# tviic2d6m register map
Vendor: Infineon Technologies; Series: TVIIC2D6M; File version: 1.0
CPU: CM7 r0p1, little endian, MPU, FPU, double-precision FPU, I-cache, D-cache, VTOR, ITCM, DTCM, 3 interrupt priority bits, 16 interrupts
Registers are 32-bit, read-write, reset 0x0 unless marked. A register's access mark holds for its fields unless they carry their own. Offsets are from the block's base; [hi:lo] are bit positions; lines under a group give offsets from that group; {n}, {i} and the like mark numbered series; 'fields as' and 'values as' point back to an identical list; <NAME> marks a mode.

## BACKUP — SRSS Backup Domain (ver3p3)
Base 0x40270000
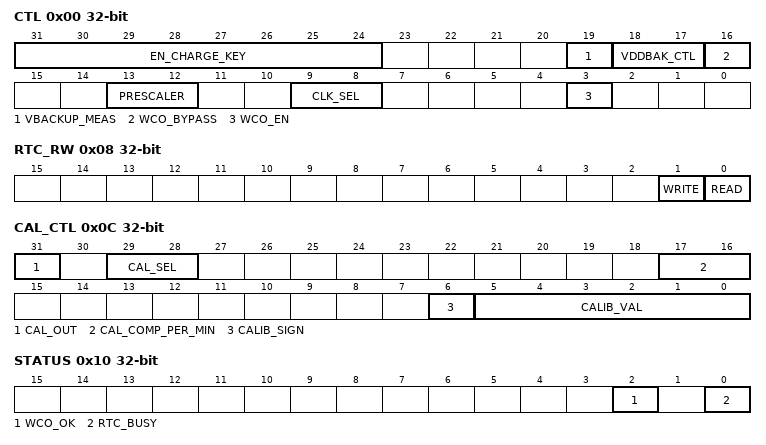
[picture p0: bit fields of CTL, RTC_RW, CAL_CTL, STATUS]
0x00 CTL — Control
  [31:24] EN_CHARGE_KEY — When set to 3C, the supercap charger circuit is enabled. Any other code disables the supercap charger. THIS CHARGING CIRCUIT IS FOR A SUPERCAP ONLY AND CANNOT SAFELY CHARGE A BATTERY. DO NOT WRITE THIS KEY WHEN VBACKUP IS CONNECTED TO A BATTERY.
  [19] VBACKUP_MEAS — Connect vbackup supply to the vbackup_meas output for measurement by an ADC attached to amuxbusa_adft_vddd. The vbackup_meas signal is scaled to 10 percent of vbackup, so it is within the supply range of the ADC.
  [18:17] VDDBAK_CTL — Controls the behavior of the switch that generates vddbak from vbackup or vddd. 0: automatically select vddd if its brownout detector says it is valid. If the brownout says its not valid, then use vmax which is the highest of vddd or vbackup. 1,2,3: force vddbak and vmax to select vbackup, regardless of its voltage.
  [16] WCO_BYPASS — Configures the WCO for different board-level connections to the WCO pins. For example, this can be used to connect an external watch crystal oscillator instead of a watch crystal. In all cases, the two related GPIO pins (WCO input and output pins) must be configured as analog connections using GPIO registers, and they must be hooked at the board level as described below. Configure this field before enabling the WCO, and do not change this setting when WCO_EN=1. 0: Watch crystal. Connect a 32.768 kHz watch crystal between WCO input and output pins. 1: Clock signal, either a square wave or sine wave. See PRESCALER field for connection information.
  [13:12] PRESCALER
  [9:8] CLK_SEL — Clock select for RTC clock
    0=WCO (Watch-crystal oscillator input, available in Active, DeepSleep, Hibernate, and XRES.); 1=ALTBAK (This allows to use the LFCLK selection as an alternate backup domain clock. Note that LFCLK is only available in Active and DeepSleep power modes. Note that LFCLK clock glitches can propagate into the backup logic when the clock is stopped. For this reason, if the WCO or ILO is intended as the clock source then choose it directly instead of routing through LFCLK.); 2=ILO (Internal Low frequency Oscillator, available in Active, DeepSleep, Hibernate, and XRES. For Hibernate operation CLK_ILO_CONFIG. ILO_BACKUP must be set. If there are multiple ILO, this is ILO0.); 3=LPECO_PRESCALER (Low-power external crystal oscillator prescaler output, available in Active, DeepSleep, Hibernate, and XRES.)
  [3] WCO_EN — Watch-crystal oscillator (WCO) enable. If there is a write in progress when this bit is cleared, the WCO will be internally kept on until the write completes. After enabling the WCO software must wait until STATUS.WCO_OK=1 before configuring any component that depends on clk_lf/clk_bak, like for example RTC or WDTs. Follow the procedure in BACKUP_RTC_RW to access this bit.
0x08 RTC_RW — RTC Read Write register
  [1] WRITE — Write bit Only when this bit is set can the RTC registers be written to (otherwise writes are ignored). This bit cannot be set if the RTC is still busy with a previous update (see RTC_BUSY bit) or if the Read bit is set or getting set. The user writes to the RTC user registers, when the Write bit is cleared by the user then the user registers content is copied to the actual RTC registers. Only user RTC registers that were written to will get copied, others will not be affected. When the SECONDS field is updated then TICKS will also be reset (WDT is not affected). When the Write bit is cleared by a reset (brown out/DeepSleep) then the RTC update will be ignored/lost. Do not set the Write bit if the RTC if the RTC is still busy with a previous update (see RTC_BUSY). Do not set the Write bit at the same time that the Read bit is cleared.
  [0] READ — Read bit When this bit is set the RTC registers will be copied to user registers and frozen so that a coherent RTC value can safely be read. The RTC will keep on running. Do not set the read bit if the RTC is still busy with a previous update (see RTC_BUSY bit) or if the Write bit is set. Do not set the Read bit at the same time that the Write bit is cleared.
0x0C CAL_CTL — Oscillator calibration for absolute frequency
  [31] CAL_OUT — Output enable for wave signal for calibration and allow CALIB_VAL to be written.
  [29:28] CAL_SEL — Select calibration wave output signal
    0=CAL512 (512Hz wave, not affected by calibration setting (not supported for 50/60Hz input clock: CTL.PRESCALER!=0)); 1=RSVD (N/A); 2=CAL2 (2Hz wave, includes the effect of the calibration setting, (not supported for 50/60Hz input clock: CTL.PRESCALER!=0)); 3=CAL1 (1Hz wave, includes the effect of the calibration setting (supported for all input clocks))
  [17:16] CAL_COMP_PER_MIN — Select how many time calibration is performed per minute per step of 64 , each time a 64 step is added or substracted one unit 2/4/8/16*CALIB_VAL is substracted.
    0=Calibration of 64 each is performed twice per minute for 2*CALIB_VAL per hour; 1=Calibration of 64 each is performed four times per minute for 4*CALIB_VAL per hour; 2=Calibration of 64 each is performed eight times per minute for 8*CALIB_VAL per hour; 3=Ca6libration of 64 each is performed sixteen times per minute for 16*CALIB_VAL per hour
  [6] CALIB_SIGN — Calibration sign: 0= Negative sign: remove pulses (it takes more clock ticks to count one second) 1= Positive sign: add pulses (it takes less clock ticks to count one second)
  [5:0] CALIB_VAL — Calibration value for absolute frequency (at a fixed temperature). Each step causes 128 ticks to be added or removed each hour. Effectively that means that each step is 1.085ppm (= 128/(60*60*32,768)) when CAL_COMP_PER_MIN is set at default value. Positive values 0x01-0x3c (1..60) add pulses, negative values remove pulses, thus giving a range of +/-65.1 ppm (limited by 60 minutes per hour, not the range of this field) when CAL_COMP_PER_MIN is set at default value . Calibration is performed hourly, starting at 59 minutes and 59 seconds, and applied as 64 ticks every 30 seconds until there have been 2*CALIB_VAL adjustments when CAL_COMP_PER_MIN is set at default value .
0x10 STATUS ro
  [2] WCO_OK — Indicates that output has transitioned.
  [0] RTC_BUSY — Pending RTC write
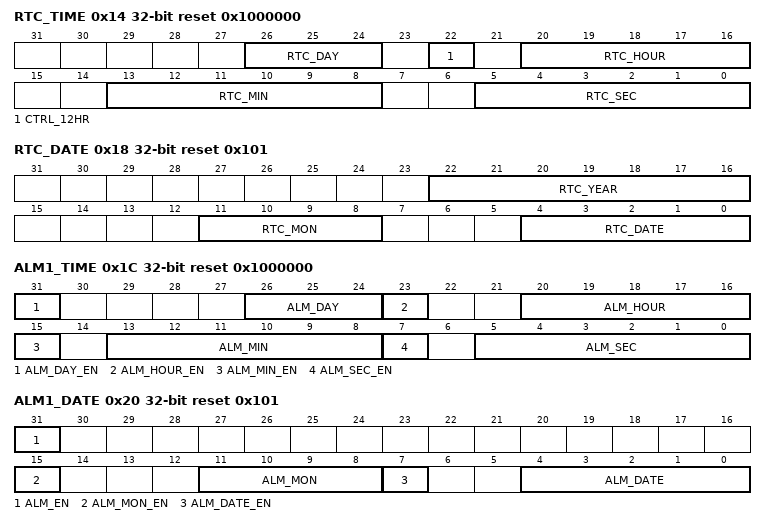
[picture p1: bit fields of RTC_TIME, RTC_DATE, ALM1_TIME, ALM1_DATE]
0x14 RTC_TIME reset 0x1000000 — Calendar Seconds, Minutes, Hours, Day of Week
  [26:24] RTC_DAY — Calendar Day of the week, 1-7 It is up to the user to define the meaning of the values, but 1=Monday is recommended
  [22] CTRL_12HR — Select 12/24HR mode: 1=12HR, 0=24HR
  [20:16] RTC_HOUR — Calendar hours, value depending on 12/24HR mode 0=24HR: [20:16]=0-23 1=12HR: [20]:0=AM, 1=PM, [19:16]=1-12
  [13:8] RTC_MIN — Calendar minutes, 0-59
  [5:0] RTC_SEC — Calendar seconds, 0-59
0x18 RTC_DATE reset 0x101 — Calendar Day of Month, Month, Year
  [22:16] RTC_YEAR — Calendar year, 0-99
  [11:8] RTC_MON — Calendar Month, 1-12
  [4:0] RTC_DATE — Calendar Day of the Month, 1-31 Automatic Leap Year Correction
0x1C ALM1_TIME reset 0x1000000 — Alarm 1 Seconds, Minute, Hours, Day of Week
  [31] ALM_DAY_EN — Alarm Day of the Week enable: 0=ignore, 1=match
  [26:24] ALM_DAY — Alarm Day of the week, 1-7 It is up to the user to define the meaning of the values, but 1=Monday is recommended
  [23] ALM_HOUR_EN — Alarm hour enable: 0=ignore, 1=match
  [20:16] ALM_HOUR — Alarm hours, value depending on 12/24HR mode 24HR: [4:0]=0-23 12HR: [4]:0=AM, 1=PM, [3:0]=1-12
  [15] ALM_MIN_EN — Alarm minutes enable: 0=ignore, 1=match
  [13:8] ALM_MIN — Alarm minutes, 0-59
  [7] ALM_SEC_EN — Alarm second enable: 0=ignore, 1=match
  [5:0] ALM_SEC — Alarm seconds, 0-59
0x20 ALM1_DATE reset 0x101 — Alarm 1 Day of Month, Month
  [31] ALM_EN — Master enable for alarm 1. 0: Alarm 1 is disabled. Fields for date and time are ignored. 1: Alarm 1 is enabled. Alarm triggers whenever the new date and time matches all the enabled date and time fields, which can happen more than once depending on configuration. If none of the date and time fields are enabled, then this alarm triggers once every second.
  [15] ALM_MON_EN — Alarm Month enable: 0=ignore, 1=match
  [11:8] ALM_MON — Alarm Month, 1-12
  [7] ALM_DATE_EN — Alarm Day of the Month enable: 0=ignore, 1=match
  [4:0] ALM_DATE — Alarm Day of the Month, 1-31 Leap Year corrected
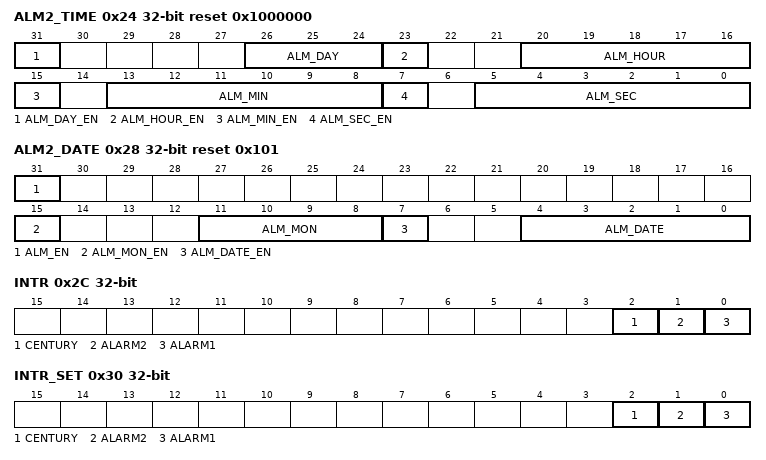
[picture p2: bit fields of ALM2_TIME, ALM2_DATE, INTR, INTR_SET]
0x24 ALM2_TIME reset 0x1000000 — Alarm 2 Seconds, Minute, Hours, Day of Week
  fields as ALM1_TIME
0x28 ALM2_DATE reset 0x101 — Alarm 2 Day of Month, Month
  [31] ALM_EN — Master enable for alarm 2. 0: Alarm 2 is disabled. Fields for date and time are ignored. 1: Alarm 2 is enabled. Alarm triggers whenever the new date and time matches all the enabled date and time fields, which can happen more than once depending on configuration. If none of the date and time fields are enabled, then this alarm triggers once every second.
  [15] ALM_MON_EN — Alarm Month enable: 0=ignore, 1=match
  [11:8] ALM_MON — Alarm Month, 1-12
  [7] ALM_DATE_EN — Alarm Day of the Month enable: 0=ignore, 1=match
  [4:0] ALM_DATE — Alarm Day of the Month, 1-31 Leap Year corrected
0x2C INTR — Interrupt request register
  [2] CENTURY write-1-clears — Century overflow interrupt
  [1] ALARM2 write-1-clears — Alarm 2 Interrupt
  [0] ALARM1 write-1-clears — Alarm 1 Interrupt
0x30 INTR_SET — Interrupt set request register
  [2] CENTURY write-1-sets — Write with '1' to set corresponding bit in interrupt request register.
  [1] ALARM2 write-1-sets — Write with '1' to set corresponding bit in interrupt request register.
  [0] ALARM1 write-1-sets — Write with '1' to set corresponding bit in interrupt request register.
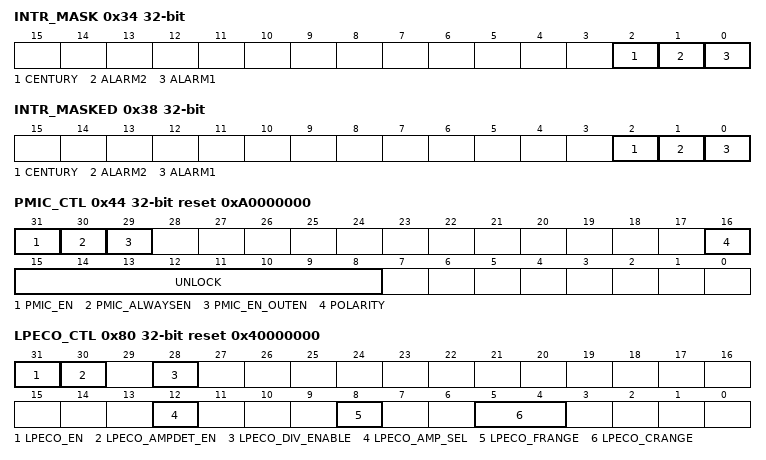
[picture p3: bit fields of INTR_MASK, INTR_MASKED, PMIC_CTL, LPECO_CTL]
0x34 INTR_MASK — Interrupt mask register
  [2] CENTURY — Mask bit for corresponding bit in interrupt request register.
  [1] ALARM2 — Mask bit for corresponding bit in interrupt request register.
  [0] ALARM1 — Mask bit for corresponding bit in interrupt request register.
0x38 INTR_MASKED ro — Interrupt masked request register
  [2] CENTURY — Logical and of corresponding request and mask bits.
  [1] ALARM2 — Logical and of corresponding request and mask bits.
  [0] ALARM1 — Logical and of corresponding request and mask bits.
0x44 PMIC_CTL reset 0xA0000000 — PMIC control register
  [31] PMIC_EN — Enable for external PMIC that supplies vddd (if present). This bit will only clear if UNLOCK was written correctly in a previous write operation and PMIC_ALWAYSEN=0. When PMIC_EN=0, the system functions normally until vddd is no longer present (OFF w/Backup mode). Firmware can set this bit, if it does so before vddd is actually removed. This bit is also set by any RTC alarm or PMIC pin wakeup event regardless of UNLOCK setting.
  [30] PMIC_ALWAYSEN write-1-sets — Override normal PMIC controls to prevent accidentally turning off the PMIC by errant firmware. 0: Normal operation, PMIC_EN and PMIC_OUTEN work as described 1: PMIC_EN and PMIC_OUTEN are ignored and the output pad is forced enabled. Note: This bit is a write-once bit until the next backup reset.
  [29] PMIC_EN_OUTEN — Output enable for the output driver in the PMIC_EN pad. 0: Output pad is tristate for PMIC_EN pin. This can allow this pin to be used for another purpose. Tristate condition is kept only if the UNLOCK key (0x3A) is present 1: Output pad is enabled for PMIC_EN pin.
  [16] POLARITY
  [15:8] UNLOCK — This byte must be set to 0x3A for PMIC to be disabled. When the UNLOCK code is not present: writes to PMIC_EN field are ignored and the hardware ignores the value in PMIC_EN. Do not change PMIC_EN in the same write cycle as setting/clearing the UNLOCK code; do these in separate write cycles.
0x48 RESET — Backup reset register
  [31] RESET write-1-sets — Writing 1 to this register resets the backup logic. Hardware clears it when the reset is complete. After setting this register, firmware should confirm it reads as 0 before attempting to write other backup registers.
0x80 LPECO_CTL reset 0x40000000 — Low-power external crystal oscillator control
  [31] LPECO_EN — Master enable for LPECO oscillator. This also disables the LPECO prescaler.
  [30] LPECO_AMPDET_EN — Minimum amplitude detector enable/disable. Ignored when LPECO_EN==0. 0: Initially enabled, and then automatically disabled when amplitude detector detects sufficient amplitude. 1: Keep minimum amplitude detector enabled as long as LPECO is enabled.
  [28] LPECO_DIV_ENABLE — LPECO prescaler enable. Do not set this to '1' when LPECO_EN==0. SW sets this field to '1' to enable the divider and HW sets this field to '0' to indicate that divider enabling has completed. When the divider is enabled, its integer and fractional counters are initialized to '0'. HW sets the LPECO_DIV_ENABLE field to '0' when the enabling is performed and HW set CLK_LPECO_PRESCALER.ENABLED to '1' when the enabling is performed.
  [12] LPECO_AMP_SEL — Selects the oscillation amplitude. WARNING: the crystal can be permanently damaged by selecting an amplitude that exceeds the crystal limits. 0: maximum amplitude is 1.35V. This is the lowest power setting. 1: maximum amplitude is 1.8V. This is the lowest jitter setting.
  [8] LPECO_FRANGE — Specifies the crystal frequency range. 0: Crystal frequency is in range [4, 6) MHz 1: Crystal frequency is in range [6, 8] MHz. Use this setting for 6 MHz.
  [5:4] LPECO_CRANGE — Specifies the load capacitance of the chosen crystal. 2'b00: load is in range [5pF, 10pF], 2'b01: load is in range (10pF, 15pF], 2'b10: load is in range (15pF, 20pF], 2'b11: load is in range (20pF, 25pF]
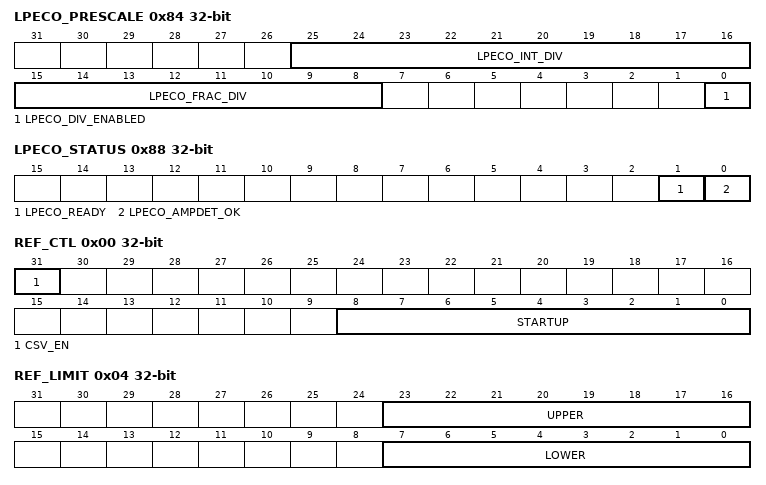
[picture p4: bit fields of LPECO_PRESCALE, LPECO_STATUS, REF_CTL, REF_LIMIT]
0x84 LPECO_PRESCALE — Low-power external crystal oscillator prescaler
  [25:16] LPECO_INT_DIV — Integer divide value allows for LPECO frequencies up to 8MHz to generate 32768 Hz. Subtract one from the desired divide value when writing this field. For example, to divide by 1, write LPECO_INT_DIV=0. Do not change this setting when LPECO Prescaler is enabled.
  [15:8] LPECO_FRAC_DIV — Fractional value, sufficient to get prescaler output within the +/-65ppm calibration range. Do not change this setting when LPECO Prescaler is enabled.
  [0] LPECO_DIV_ENABLED ro — LPECO prescaler enabled. HW sets this field to '1' as a result of an BACKUP_LPECO_CTL.LPECO_DIV_ENABLE. HW sets this field to '0' as a result of writing CLK_LPECO_CONFIG.LPECO_EN==0. This field does not update unless LPECO clock is toggling.
0x88 LPECO_STATUS ro — Low-power external crystal oscillator status
  [1] LPECO_READY — Indicates the LPECO has had enough time to start. This field is driven by a stabilization counter clocked by IMO.
  [0] LPECO_AMPDET_OK — Indicates sufficient oscillation amplitude reported by LPECO amplitude detector. This field will read as zero when the amplitude detector is off (see LPECO_CTL.LPECO_AMPDET_EN).
0x100 CSV_BAK group — CSV registers for clk_bak clock
  0x00 CSV group — clk_bak Backup domain Clock Supervisor registers
    0x00 REF_CTL — Clock Supervision Reference Control
      [31] CSV_EN — Enables clock supervision, both frequency and loss. CSV in Active domain: Clock supervision is reset during DeepSleep and Hibernate modes. When enabled it begins operating automatically after a DeepSleep wakeup, but it must be reconfigured after Hibernate wakeup. CSV in DeepSleep domain: Clock supervision is reset during Hibernate mode. It must be reconfigured after Hibernate wakeup. CSV in Backup domain: Clock supervision operates during Hibernate mode, can be configured to wake from Hibernate, and continues operating during reboot. A CSV error detection is reported to the Fault structure.
      [8:0] STARTUP — Startup delay time -1 (in reference clock cycles), after enable, from reference clock start to monitored clock start. At a minimum (both clocks running): STARTUP >= (PERIOD +3) * FREQ_RATIO - UPPER, with FREQ_RATIO = (Reference frequency / Monitored frequency) On top of that the actual clock startup delay and the margin for accuracy of both clocks must be added.
    0x04 REF_LIMIT — Clock Supervision Reference Limits
      [23:16] UPPER — Cycle time upper limit. Set the upper limit -1, in reference clock cycles, before (or same time) the next monitored clock event must happen. If a monitored clock event does not happen before this limit is reached, or does not happen at all (clock loss), a CSV error is detected.
      [7:0] LOWER — Cycle time lower limit. Set the lower limit -1, in reference clock cycles, before the next monitored clock event is allowed to happen. If a monitored clock event happens before this limit is reached a CSV error is detected. LOWER must be at least 1 less than UPPER. In case the clocks are asynchronous LOWER must be at least 3 less than UPPER.
    0x08 MON_CTL — Clock Supervision Monitor Control
      [7:0] PERIOD — Period time. Set the Period -1, in monitored clock cycles, before the next monitored clock event happens. PERIOD <= (UPPER+1) / FREQ_RATIO -1, with FREQ_RATIO = (Reference frequency / Monitored frequency) In case the clocks are asynchronous: PERIOD <= UPPER / FREQ_RATIO -1 Additionally margin must be added for accuracy of both clocks.
{0x1000+4i} BREG[{i}] (i=0..63) — Backup register region
  [31:0] BREG — Backup memory that contains application-specific data. Memory is retained on vbackup supply.
